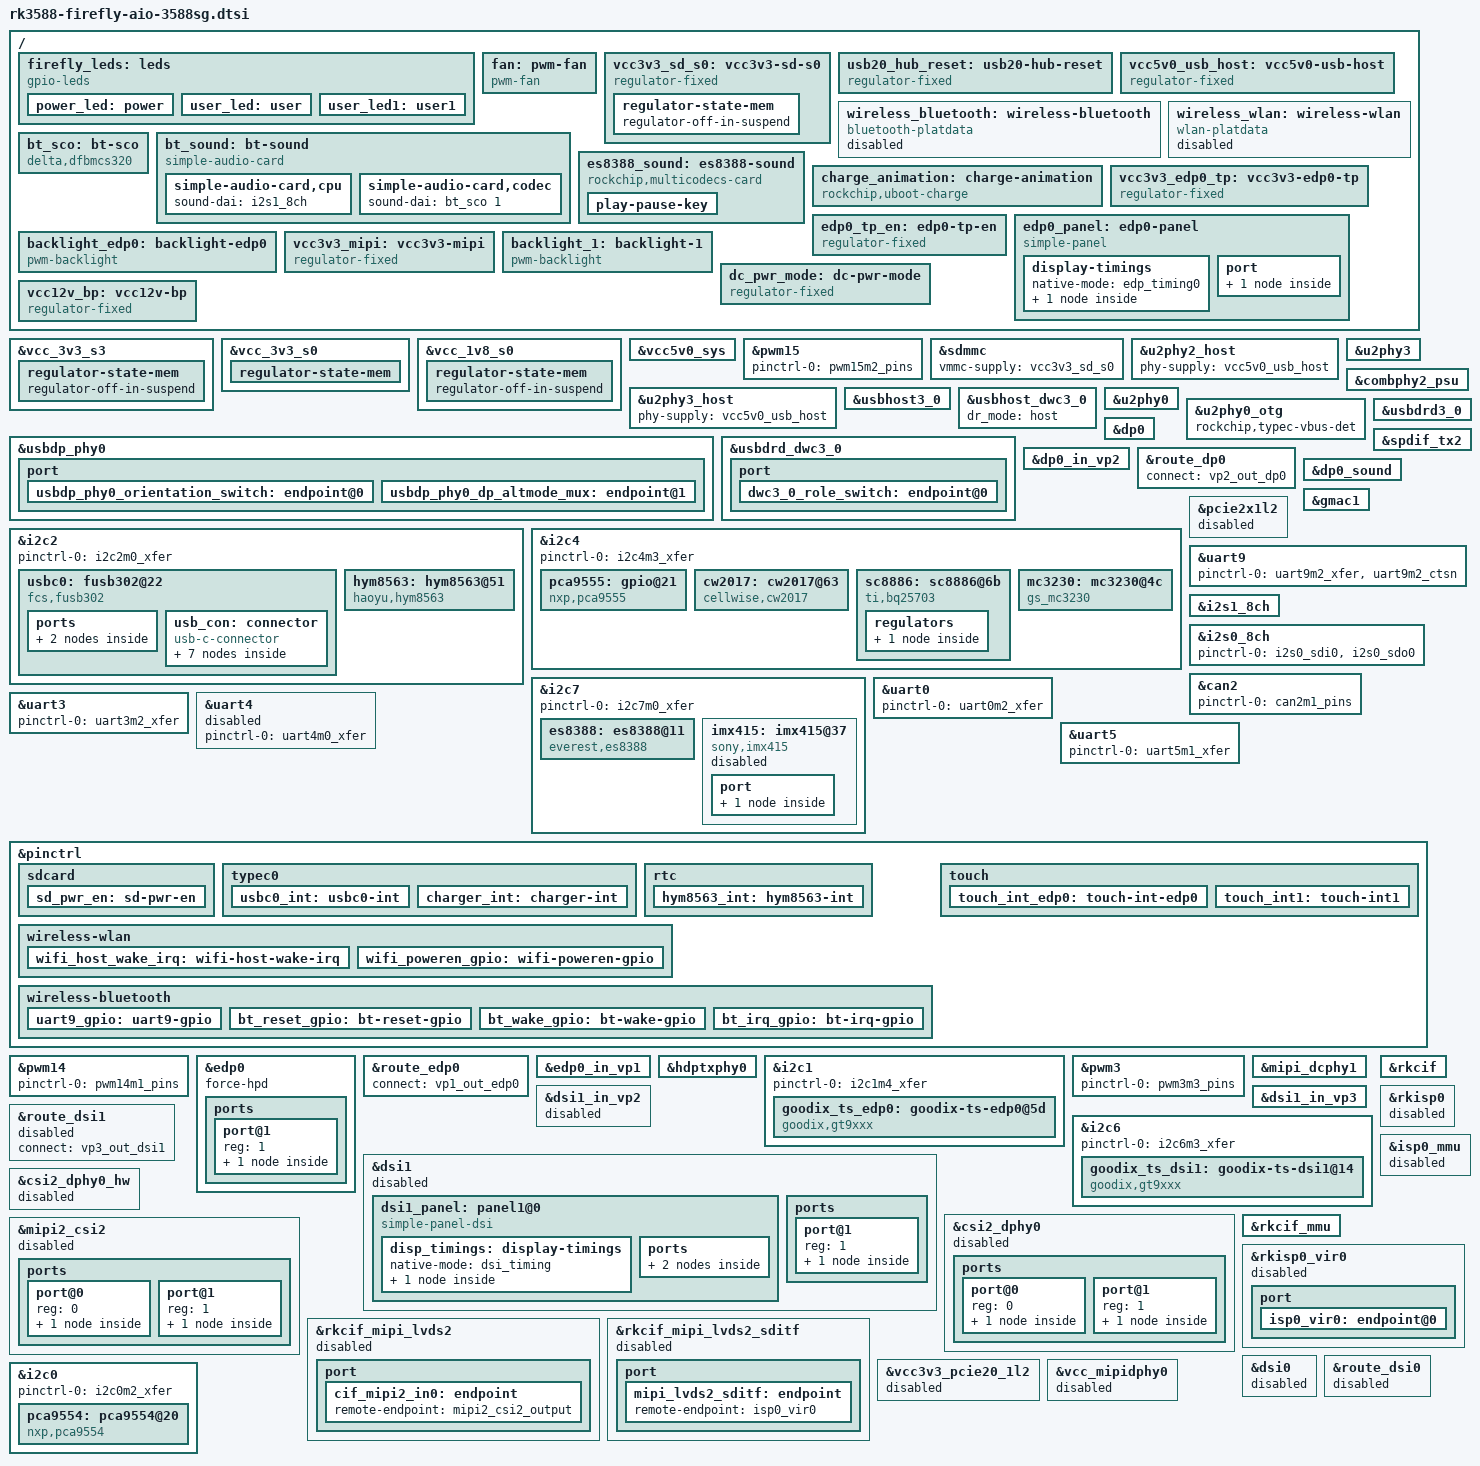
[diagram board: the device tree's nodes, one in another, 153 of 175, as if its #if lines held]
// SPDX-License-Identifier: (GPL-2.0+ OR MIT)
/*
 * Copyright (c) 2023 T-chip Firefly Electronics Co., Ltd.
 *
 */

#include "rk3588-firefly-common.dtsi"

/ {
#ifdef FF_LEDS
	firefly_leds: leds {
		compatible = "gpio-leds";
		status = "okay";

		power_led: power {
			label = ":power";
			linux,default-trigger = "ir-power-click";
			default-state = "on";
			gpios = <&pca9555 PCA_IO1_7 GPIO_ACTIVE_HIGH>;
		};

		user_led: user {
			label = ":user";
			linux,default-trigger = "ir-user-click";
			default-state = "off";
			gpios = <&pca9555 PCA_IO1_6 GPIO_ACTIVE_HIGH>;
		};

		user_led1: user1 {
			label = ":user1";
			linux,default-trigger = "ir-user1-click";
			default-state = "off";
			gpios = <&pca9555 PCA_IO1_5 GPIO_ACTIVE_HIGH>;
		};
	};
#endif

#ifdef FF_FAN
	fan: pwm-fan {
		status = "okay";
		compatible = "pwm-fan";
		#cooling-cells = <2>;
		fan-supply = <&vcc12v_dcin>;
		pwms = <&pwm15 0 50000 0>;
	};
#endif

#ifdef FF_SDCARD
	vcc3v3_sd_s0: vcc3v3-sd-s0 {
		status = "okay";
		compatible = "regulator-fixed";
		regulator-name = "vcc3v3_sd_s0";
		enable-active-high;
		regulator-min-microvolt = <3300000>;
		regulator-max-microvolt = <3300000>;
		gpio = <&gpio3 RK_PC6 GPIO_ACTIVE_HIGH>;
		pinctrl-names = "default";
		pinctrl-0 = <&sd_pwr_en>;
		vin-supply = <&vcc_3v3_s3>;
		regulator-state-mem {
			regulator-off-in-suspend;
		};
	};
#endif

#ifdef FF_USB20_HOST0
	usb20_hub_reset: usb20-hub-reset {
		status = "okay";
		compatible = "regulator-fixed";
		regulator-name = "usb20_hub_reset";
		regulator-boot-on;
		regulator-always-on;
		enable-active-high;
		gpio = <&pca9555 PCA_IO1_4 GPIO_ACTIVE_HIGH>;
	};
#endif

#if defined(FF_USB20_HOST0) || defined(FF_USB30_HOST)
	vcc5v0_usb_host: vcc5v0-usb-host {
		status = "okay";
		compatible = "regulator-fixed";
		regulator-name = "vcc5v0_usb_host";
		enable-active-high;
		regulator-boot-on;
		regulator-always-on;
		regulator-min-microvolt = <5000000>;
		regulator-max-microvolt = <5000000>;
		gpio = <&gpio4 RK_PB5 GPIO_ACTIVE_HIGH>;
		vin-supply = <&vcc5v0_usb>;
	};
#endif

#ifdef FF_WIFIBT
	wireless_bluetooth: wireless-bluetooth {
		compatible = "bluetooth-platdata";
		clocks = <&hym8563>;
		clock-names = "ext_clock";
		uart_rts-gpios = <&gpio3 RK_PD2 GPIO_ACTIVE_LOW>;
		pinctrl-names = "default", "rts_gpio";
		pinctrl-0 = <&uart9m2_rtsn>, <&bt_reset_gpio>, <&bt_wake_gpio>, <&bt_irq_gpio>;
		pinctrl-1 = <&uart9_gpio>;
		BT,reset-gpios      = <&gpio0 RK_PD0 GPIO_ACTIVE_HIGH>;  // BT_REG_ON
		BT,wake-gpios       = <&gpio0 RK_PC6 GPIO_ACTIVE_HIGH>;  // BT_WAKE_APB
		BT,wake_host-gpios  = <&gpio0 RK_PC5 GPIO_ACTIVE_HIGH>;  // BT_HOST_WAKE
		status = "okay";
	};

	wireless_wlan: wireless-wlan {
		compatible = "wlan-platdata";
		wifi_chip_type = "ap6275p";
		pinctrl-names = "default";
		pinctrl-0 = <&wifi_host_wake_irq>, <&wifi_poweren_gpio>;
		WIFI,host_wake-gpios = <&gpio0 RK_PA0 GPIO_ACTIVE_HIGH>;  // WIFI_HOST_WAKE
		WIFI,poweren-gpios   = <&gpio0 RK_PC7 GPIO_ACTIVE_HIGH>;  // WL_REG_ON
		status = "okay";
	};

	bt_sco: bt-sco {
		status = "okay";
		compatible = "delta,dfbmcs320";
		#sound-dai-cells = <1>;
	};

	bt_sound: bt-sound {
		status = "okay";
		compatible = "simple-audio-card";
		simple-audio-card,format = "dsp_a";
		simple-audio-card,bitclock-inversion = <0>;
		simple-audio-card,mclk-fs = <256>;
		simple-audio-card,name = "rockchip,bt";
		simple-audio-card,cpu {
			sound-dai = <&i2s1_8ch>;
		};
		simple-audio-card,codec {
			sound-dai = <&bt_sco 1>;
		};
	};
#endif

#ifdef FF_CODEC_ES8388
	es8388_sound: es8388-sound {
		status = "okay";
		compatible = "rockchip,multicodecs-card";
		rockchip,card-name = "rockchip-es8388";
		//hp-det-gpio = <&gpio3 RK_PC1 GPIO_ACTIVE_LOW>;
		io-channels = <&saradc 4>;
		io-channel-names = "adc-detect";
		keyup-threshold-microvolt = <1800000>;
		poll-interval = <100>;	
		spk-con-gpio = <&gpio1 RK_PC0 GPIO_ACTIVE_HIGH>;
		//hp-con-gpio = <&gpio3 RK_PB2 GPIO_ACTIVE_HIGH>;
		rockchip,format = "i2s";
		rockchip,mclk-fs = <256>;
		rockchip,cpu = <&i2s0_8ch>;
		rockchip,codec = <&es8388>;
		rockchip,audio-routing =
			"Headphone", "LOUT1",
			"Headphone", "ROUT1",
			"Speaker", "LOUT2",
			"Speaker", "ROUT2",
			"Headphone", "Headphone Power",
			"Headphone", "Headphone Power",
			"Speaker", "Speaker Power",
			"Speaker", "Speaker Power",
			"LINPUT1", "Main Mic",
			"LINPUT2", "Main Mic",
			"RINPUT1", "Headset Mic",
			"RINPUT2", "Headset Mic";
		//pinctrl-names = "default";
		//pinctrl-0 = <&hp_det>;
		play-pause-key {
			label = "playpause";
			linux,code = <KEY_PLAYPAUSE>;
			press-threshold-microvolt = <2000>;
		};
	};
#endif

	charge_animation: charge-animation {
		status = "okay";
		compatible = "rockchip,uboot-charge";
		rockchip,uboot-charge-on = <1>;
		rockchip,android-charge-on = <0>;
		rockchip,uboot-exit-charge-level = <2>;
		rockchip,uboot-exit-charge-auto = <1>;
		rockchip,uboot-low-power-voltage = <6144>;
		rockchip,screen-on-voltage = <6144>;
	};
};

&vcc_3v3_s3 {
	regulator-state-mem {
		regulator-off-in-suspend;
	};
};

&vcc_3v3_s0 {
	regulator-state-mem {
		regulator-off-in-suspend;
		regulator-suspend-microvolt = <3300000>;
	};
};

&vcc_1v8_s0 {
	regulator-state-mem {
		regulator-off-in-suspend;
	};

};

&vcc5v0_sys{
	enable-active-high;
	gpio = <&gpio4 RK_PA0 GPIO_ACTIVE_HIGH>;
};

#ifdef FF_FAN
&pwm15 {
	status = "okay";
	pinctrl-0 = <&pwm15m2_pins>;
};
#endif

#ifdef FF_SDCARD
&sdmmc {
	status = "okay";
	vmmc-supply = <&vcc3v3_sd_s0>;
};
#endif

#ifdef FF_USB20_HOST0
&u2phy2_host {
	status = "okay";
	phy-supply = <&vcc5v0_usb_host>;
};
#endif

#ifdef FF_USB30_HOST
&u2phy3 {
	status = "okay";
};

&u2phy3_host {
	status = "okay";
	phy-supply = <&vcc5v0_usb_host>;
};

&combphy2_psu {
	status = "okay";
};

&usbhost3_0 {
	status = "okay";
};

&usbhost_dwc3_0 {
	status = "okay";
	dr_mode = "host";
};
#endif

#ifdef FF_TYPEC0_FULL
&u2phy0 {
	status = "okay";
};

&u2phy0_otg {
	status = "okay";
	rockchip,typec-vbus-det;
};

&usbdp_phy0 {
	status = "okay";
	orientation-switch;
	mode-switch;
	svid = <0xff01>;
	sbu1-dc-gpios = <&gpio1 RK_PB0 GPIO_ACTIVE_HIGH>;
	sbu2-dc-gpios = <&gpio1 RK_PA0 GPIO_ACTIVE_HIGH>;

	port {
		#address-cells = <1>;
		#size-cells = <0>;
		usbdp_phy0_orientation_switch: endpoint@0 {
			reg = <0>;
			remote-endpoint = <&usbc0_orien_sw>;
		};

		usbdp_phy0_dp_altmode_mux: endpoint@1 {
			reg = <1>;
			remote-endpoint = <&dp_altmode_mux>;
		};
	};
};

&usbdrd3_0 {
	status = "okay";
};

&usbdrd_dwc3_0 {
	status = "okay";
	dr_mode = "otg";
	usb-role-switch;
	port {
		#address-cells = <1>;
		#size-cells = <0>;
		dwc3_0_role_switch: endpoint@0 {
			reg = <0>;
			remote-endpoint = <&usbc0_role_sw>;
		};
	};
};

&dp0 {
        status = "okay";
};

&dp0_in_vp2 {
	status = "okay";
};

&spdif_tx2{
        status = "okay";
};

&route_dp0 {
    status = "okay";
    connect = <&vp2_out_dp0>;
};

&dp0_sound{
        status = "okay";
};
#endif

&i2c2 {
	status = "okay";
	pinctrl-names = "default";
	pinctrl-0 = <&i2c2m0_xfer>;

#ifdef FF_TYPEC0_FULL
	usbc0: fusb302@22 {
		compatible = "fcs,fusb302";
		reg = <0x22>;
		interrupt-parent = <&gpio0>;
		interrupts = <RK_PC4 IRQ_TYPE_LEVEL_LOW>;
		int-n-gpios = <&gpio0 RK_PC4 GPIO_ACTIVE_LOW>;
		pinctrl-names = "default";
		pinctrl-0 = <&usbc0_int>;
		vbus-supply = <&vbus5v0_typec_charge>;
		charge-dev = <&sc8886>;
		suspend-disable-irq;
		status = "okay";

		ports {
			#address-cells = <1>;
			#size-cells = <0>;

			port@0 {
				reg = <0>;
				usbc0_role_sw: endpoint@0 {
					remote-endpoint = <&dwc3_0_role_switch>;
				};
			};
		};

		usb_con: connector {
			compatible = "usb-c-connector";
			label = "USB-C";
			data-role = "dual";
			power-role = "dual";
			try-power-role = "sink";
			op-sink-microwatt = <1000000>;
			sink-pdos =
				<PDO_FIXED(5000, 3000, PDO_FIXED_USB_COMM)
				 PDO_FIXED(9000, 3000, PDO_FIXED_USB_COMM)
				 PDO_FIXED(12000, 2000, PDO_FIXED_USB_COMM)>;
			source-pdos = <PDO_FIXED(5000, 3000, PDO_FIXED_USB_COMM)>;
			mode-switch = <&dp0>;

			altmodes {
				#address-cells = <1>;
				#size-cells = <0>;

				altmode@0 {
					reg = <0>;
					svid = /bits/ 16 <0xff01>;
					vdo = <0x00001c46>;
				};
			};

			ports {
				#address-cells = <1>;
				#size-cells = <0>;

				port@0 {
					reg = <0>;
					usbc0_orien_sw: endpoint {
						remote-endpoint = <&usbdp_phy0_orientation_switch>;
					};
				};

				port@1 {
					reg = <1>;
					dp_altmode_mux: endpoint {
						remote-endpoint = <&usbdp_phy0_dp_altmode_mux>;
					};
				};
			};
		};
	};
#endif

#ifdef FF_RTC
	hym8563: hym8563@51 {
		compatible = "haoyu,hym8563";
		reg = <0x51>;
		#clock-cells = <0>;
		clock-frequency = <32768>;
		clock-output-names = "hym8563";
		pinctrl-names = "default";
		pinctrl-0 = <&hym8563_int>;
		interrupt-parent = <&gpio0>;
		interrupts = <RK_PB0 IRQ_TYPE_LEVEL_LOW>;
		wakeup-source;
		status = "okay";
	};
#endif
};

&i2c4 {
	status = "okay";
	pinctrl-names = "default";
	pinctrl-0 = <&i2c4m3_xfer>;
	
#ifdef FF_PCA9555
	pca9555: gpio@21 {
		status = "okay";
		compatible = "nxp,pca9555";
		reg = <0x21>;
		gpio-controller;
		#gpio-cells = <2>;
		gpio-group-num = <200>;
	};
#endif

#ifdef FF_TYPEC0_FULL
	cw2017: cw2017@63 {
		status = "okay";
		compatible = "cellwise,cw2017";
		reg = <0x63>;
		cellwise,battery-profile = /bits/ 8
			<
			0x3C 0x00 0x00 0x00 0x00 0x00 0x00 0x00
			0xB0 0xC4 0xBF 0xB9 0x9B 0x97 0xE0 0xCF
			0xC1 0xCD 0xBB 0x9D 0x88 0x7C 0x65 0x56
			0x52 0x50 0x4E 0x97 0x79 0xD2 0xDE 0xFF
			0xE5 0xB4 0x71 0x7C 0xB0 0xC5 0xAE 0x93
			0x9D 0xB5 0xCF 0xD5 0xC6 0xB0 0x99 0x89
			0x82 0x85 0x91 0xA8 0xC1 0xC9 0xB0 0x43
			0x00 0x00 0x90 0x02 0x00 0x00 0x00 0x00
			0x00 0x00 0x64 0x00 0x00 0x00 0x00 0x00
			0x00 0x00 0x00 0x00 0x00 0x00 0x00 0xA2
			>;
		cellwise,dual-cell;
		cellwise,monitor-interval-ms = <5000>;
		cellwise,alert-level = <10>;
		cellwise,design-capacity-amh = <5000>;
		power-supplies = <&sc8886>;
		firefly,battery-max-voltage = <8400>;
		firefly,battery-min-voltage = <6000>;
		firefly,max-temp = <45>;
		firefly,min-temp = <10>;
	};
		
	sc8886: sc8886@6b {
		status = "okay";
		compatible = "ti,bq25703";
		reg = <0x6b>;
		ti,usb-charger-detection = <&usbc0>;
		ti,charge-current = <2000000>;
		interrupt-parent = <&gpio4>;
		interrupts = <RK_PC1 IRQ_TYPE_LEVEL_LOW>;
		otg-mode-en-gpios = <&gpio4 RK_PC0 GPIO_ACTIVE_HIGH>;
		pinctrl-names = "default";
		pinctrl-0 = <&charger_int>;
		extcon = <&u2phy0>;
		ti,max-input-voltage = <20000000>;
		ti,max-input-current = <6000000>;
		ti,max-charge-voltage = <8400000>;
		ti,input-current = <2500000>;
		ti,input-current-sdp = <2500000>;
		ti,input-current-dcp = <2500000>;
		ti,input-current-cdp = <2500000>;
		ti,minimum-sys-voltage = <6144000>;
		ti,otg-voltage = <5000000>;
		ti,otg-current = <1500000>;
		pd-charge-only = <0>;
		typec0-discharge-gpios = <&gpio1 RK_PA5 GPIO_ACTIVE_HIGH>;
		regulators {
			vbus5v0_typec_charge: vbus5v0-typec-charge {
				regulator-compatible = "otg-vbus";
				regulator-name = "vbus5v0_typec_charge";
			};
		};
	};
#endif

#ifdef FF_GSENSOR
	mc3230: mc3230@4c {
		status = "okay";
		compatible = "gs_mc3230";
		reg = <0x4c>;
		type = <SENSOR_TYPE_ACCEL>;
		irq_enable = <0>;
		poll_delay_ms = <30>;
		layout = <6>;
	};
#endif
};

&i2c7 {
	status = "okay";
	pinctrl-names = "default";
	pinctrl-0 = <&i2c7m0_xfer>;

#ifdef FF_CODEC_ES8388
	es8388: es8388@11 {
		status = "okay";
		#sound-dai-cells = <0>;
		compatible = "everest,es8388", "everest,es8323";
		reg = <0x11>;
		clocks = <&mclkout_i2s0>;
		clock-names = "mclk";
		assigned-clocks = <&mclkout_i2s0>;
		assigned-clock-rates = <12288000>;
		pinctrl-names = "default";
		pinctrl-0 = <&i2s0_mclk>;
	};
#endif
};

#ifdef FF_GMAC1
&gmac1{
 	snps,reset-gpio = <&gpio1 RK_PA1 GPIO_ACTIVE_LOW>;
	tx_delay = <0x37>;
	status = "okay";
};
#endif

#if defined(FF_PCIE2_1L2) && !defined(FF_SATA0)
&pcie2x1l2 {
	reset-gpios = <&gpio3 RK_PD1 GPIO_ACTIVE_HIGH>;
	rockchip,skip-scan-in-resume;
	status = "okay";
};
#endif


#ifdef FF_WIFIBT
&uart9 {
	status = "okay";
	pinctrl-names = "default";
	pinctrl-0 = <&uart9m2_xfer &uart9m2_ctsn>;
};

&i2s1_8ch {
	status = "okay";
	pinctrl-0 = <&i2s1m0_lrck
		     &i2s1m0_sclk
		     &i2s1m0_sdi2
		     &i2s1m0_sdo3>;
	rockchip,bclk-fs = <32>;
};
#endif

#ifdef FF_CODEC_ES8388
&i2s0_8ch {
	status = "okay";
	pinctrl-0 = <&i2s0_sdi0 &i2s0_sdo0>;
};
#endif

#ifdef FF_CAN2
&can2 {
	status = "okay";
	pinctrl-names = "default";
	pinctrl-0 = <&can2m1_pins>;
};
#endif

#ifdef FF_UART
&uart0 {
	status = "okay";
	pinctrl-names = "default";
	pinctrl-0 = <&uart0m2_xfer>;
};

&uart3 {
	status = "okay";
	pinctrl-names = "default";
	pinctrl-0 = <&uart3m2_xfer>;
};

&uart4 {
	status = "okay";
	pinctrl-names = "default";
	pinctrl-0 = <&uart4m0_xfer>;
};

&uart5 {
	status = "okay";
	pinctrl-names = "default";
	pinctrl-0 = <&uart5m1_xfer>;
};
#endif

&pinctrl {
#ifdef FF_SDCARD
	sdcard {
		sd_pwr_en: sd-pwr-en {
			rockchip,pins = <3 RK_PC6 RK_FUNC_GPIO &pcfg_pull_none>;
		};
	};
#endif

#ifdef FF_TYPEC0_FULL
	typec0 {
		usbc0_int: usbc0-int {
			rockchip,pins = <0 RK_PC4 RK_FUNC_GPIO &pcfg_pull_up>;
		};

		charger_int: charger-int {
			rockchip,pins = <4 RK_PC1 RK_FUNC_GPIO &pcfg_pull_up>;
		};
	};
#endif

#ifdef FF_RTC
	rtc {
		hym8563_int: hym8563-int {
			rockchip,pins = <0 RK_PB0 RK_FUNC_GPIO &pcfg_pull_up>;
		};
	};
#endif

#ifdef FF_WIFIBT
	wireless-wlan {
		wifi_host_wake_irq: wifi-host-wake-irq {
			rockchip,pins = <0 RK_PA0 RK_FUNC_GPIO &pcfg_pull_down>;
		};

		wifi_poweren_gpio: wifi-poweren-gpio {
			rockchip,pins = <0 RK_PC7 RK_FUNC_GPIO &pcfg_pull_up>;
		};
	};

	wireless-bluetooth {
		uart9_gpio: uart9-gpio {
			rockchip,pins = <3 RK_PD2 RK_FUNC_GPIO &pcfg_pull_none>;
		};
		bt_reset_gpio: bt-reset-gpio {
			rockchip,pins = <0 RK_PD0 RK_FUNC_GPIO &pcfg_pull_none>;
		};

		bt_wake_gpio: bt-wake-gpio {
			rockchip,pins = <0 RK_PC6 RK_FUNC_GPIO &pcfg_pull_none>;
		};

		bt_irq_gpio: bt-irq-gpio {
			rockchip,pins = <0 RK_PC5 RK_FUNC_GPIO &pcfg_pull_down>;
		};
	};
#endif
};

#ifdef FF_EDP0_VP1
/* ===== inlined from top-level dts: #include "rk3588-firefly-aio-3588sg-edp0.dtsi" ===== */
// SPDX-License-Identifier: (GPL-2.0+ OR MIT)
/*
 * Copyright (c) 2023 Rockchip Electronics Co., Ltd.
 *
 */

/ {
	vcc3v3_edp0_tp: vcc3v3-edp0-tp {
		status = "okay";
		compatible = "regulator-fixed";
		regulator-name = "vcc3v3_edp0_tp";
		regulator-boot-on;
		regulator-always-on;
		enable-active-high;
		gpio = <&pca9554 PCA_IO0_1 GPIO_ACTIVE_HIGH>;
	};

	edp0_tp_en: edp0-tp-en {
		status = "okay";
		compatible = "regulator-fixed";
		regulator-name = "edp0_tp_en";
		regulator-boot-on;
		regulator-always-on;
		enable-active-high;
		gpio = <&pca9554 PCA_IO0_2 GPIO_ACTIVE_HIGH>;
	};

	edp0_panel: edp0-panel {
		status = "okay";
		compatible = "simple-panel";
		backlight = <&backlight_edp0>;
		enable-gpios = <&pca9555 PCA_IO0_3 GPIO_ACTIVE_HIGH>;
		prepare-delay-ms = <200>;

		display-timings {
			native-mode = <&edp_timing0>;
			edp_timing0: timing0 {
				clock-frequency = <533250000>;  // Min 355.52 / Typ 533.25 / Max 586.6  (MHz)
				hactive = <3840>;
				vactive = <2160>;
				hfront-porch = <48>;
				hsync-len = <32>;
				hback-porch = <100>;
				vfront-porch = <3>;
				vsync-len = <5>;
				vback-porch = <30>;
				hsync-active = <0>;
				vsync-active = <0>;
				de-active = <0>;
				pixelclk-active = <0>;
			};
		};

		port {
			panel_in_edp0: endpoint {
				remote-endpoint = <&edp0_out_panel>;
			};
		};
	};

	backlight_edp0: backlight-edp0 {
		status = "okay";
		compatible = "pwm-backlight";
		enable-gpios = <&pca9555 PCA_IO0_2 GPIO_ACTIVE_HIGH>; // EDP_BL_EN
		pwms = <&pwm14 0 50000 0>;
		brightness-levels = <
			  0   1   2   3   4   5   6   7
			  8   9  10  11  12  13  14  15
			 16  17  18  19  20  21  22  23
			 24  25  26  27  28  29  30  31
			 32  33  34  35  36  37  38  39
			 40  41  42  43  44  45  46  47
			 48  49  50  51  52  53  54  55
			 56  57  58  59  60  61  62  63
			 64  65  66  67  68  69  70  71
			 72  73  74  75  76  77  78  79
			 80  81  82  83  84  85  86  87
			 88  89  90  91  92  93  94  95
			 96  97  98  99 100 101 102 103
			104 105 106 107 108 109 110 111
			112 113 114 115 116 117 118 119
			120 121 122 123 124 125 126 127
			128 129 130 131 132 133 134 135
			136 137 138 139 140 141 142 143
			144 145 146 147 148 149 150 151
			152 153 154 155 156 157 158 159
			160 161 162 163 164 165 166 167
			168 169 170 171 172 173 174 175
			176 177 178 179 180 181 182 183
			184 185 186 187 188 189 190 191
			192 193 194 195 196 197 198 199
			200 201 202 203 204 205 206 207
			208 209 210 211 212 213 214 215
			216 217 218 219 220 221 222 223
			224 225 226 227 228 229 230 231
			232 233 234 235 236 237 238 239
			240 241 242 243 244 245 246 247
			248 249 250 251 252 253 254 255 >;
		default-brightness-level = <200>;
	};
};

&pwm14 {
	status = "okay";
	pinctrl-0 = <&pwm14m1_pins>;
};

&edp0 {
	status = "okay";
	force-hpd;
	//hpd-gpios = <&gpio1 RK_PA6 GPIO_ACTIVE_HIGH>;

	ports {
		port@1 {
			reg = <1>;
			edp0_out_panel: endpoint {
				remote-endpoint = <&panel_in_edp0>;
			};
		};
	};
};

&route_edp0 {
	status = "okay";
	connect = <&vp1_out_edp0>;
};

&edp0_in_vp1 {
	status = "okay";
};

&hdptxphy0 {
	status = "okay";
};

&i2c1 {
	status = "okay";
	pinctrl-names = "default";
	pinctrl-0 = <&i2c1m4_xfer>;

	goodix_ts_edp0: goodix-ts-edp0@5d {
		status = "okay";
		compatible = "goodix,gt9xxx";
		reg = <0x5d>;
		interrupt-parent = <&gpio1>;
		interrupts = <RK_PB2 IRQ_TYPE_LEVEL_LOW>;
		reset-gpios = <&pca9554 PCA_IO0_3 GPIO_ACTIVE_LOW>;
		irq-gpios = <&gpio1 RK_PB2 IRQ_TYPE_EDGE_FALLING>;
		irq-flags = <2>; /* 1 rising, 2 falling */
		pinctrl-names = "default";
		pinctrl-0 = <&touch_int_edp0>;
		touchscreen-size-x = <3840>;
		touchscreen-size-y = <2160>;
		goodix,slide-wakeup = <0>;
		goodix,type-a-report = <1>;
		goodix,driver-send-cfg = <1>;
		goodix,resume-in-workqueue = <0>;
		goodix,int-sync = <0>;
		goodix,esd-protect = <0>;
		goodix,auto-update-cfg = <1>;
		goodix,auto-update = <0>;
		goodix,power-off-sleep = <0>;
		goodix,pen-suppress-finger = <0>;
		goodix,has-pen = <0>;

		goodix,cfg-group2 = [
			5a 00 40 80 25 0a 7d 00 01 08
			28 05 5f 32 03 05 00 00 00 00
			00 00 00 1a 1c 1e 14 95 35 ff
			2a 2c b5 06 00 00 02 b9 03 1d
			1a 1c 1e 90 00 00 00 00 00 00
			00 1e 42 94 c5 02 07 00 00 04
			f5 20 00 c7 26 00 a6 2c 00 8a
			34 00 73 3d 00 73 00 00 00 00
			00 00 00 00 00 00 00 00 00 00
			00 00 00 00 00 00 00 00 00 00
			00 00 00 00 03 00 00 00 00 00
			00 00 00 01 02 03 04 05 06 07
			08 09 0a 0b 0c 0d 0e 0f 10 11
			12 13 14 15 16 17 18 19 1a 1b
			1c 1d 2a 29 28 27 26 25 24 23
			22 21 20 1f 1e 1d 1c 1b 19 18
			17 16 15 14 13 12 11 10 0f 0e
			0d 0c 0b 0a 09 08 07 06 05 04
			03 02 01 00 cc 01];
	};
};

&pinctrl {
	touch {
		touch_int_edp0: touch-int-edp0 {
			rockchip,pins = <1 RK_PB2 RK_FUNC_GPIO &pcfg_pull_up>;
		};
	};
};
#endif

#if defined(FF_DSI1_VP3) && !defined(FF_DSI0_LVDS101_VP3) && !defined(FF_DSI0_LVDS215_VP3)
/* ===== inlined from top-level dts: #include "rk3588-firefly-aio-3588sg-mipi-dsi1.dtsi" ===== */
// SPDX-License-Identifier: (GPL-2.0+ OR MIT)
/*
 * Copyright (c) 2023 Rockchip Electronics Co., Ltd.
 *
 */

#include <dt-bindings/display/drm_mipi_dsi.h>

/ {
	vcc3v3_mipi: vcc3v3-mipi {
		status = "okay";
		compatible = "regulator-fixed";
		regulator-name = "vcc3v3_mipi";
		regulator-boot-on;
		regulator-always-on;
		enable-active-high;
		gpio = <&pca9555 PCA_IO0_6 GPIO_ACTIVE_HIGH>;
	};

	backlight_1: backlight-1 {
		status = "okay";
		compatible = "pwm-backlight";
		enable-gpios = <&gpio4 RK_PB7 GPIO_ACTIVE_HIGH>;
		pwms = <&pwm3 0 50000 1>;
		brightness-levels = <
			 60  60  60  61  61  61  62  62
			 62  63  63  63  64  64  64  65
			 65  65  66  66  66  67  67  67
			 68  68  68  69  69  69  70  70
			 70  71  71  71  72  72  72  73
			 73  73  74  74  74  75  75  75
			 76  76  76  77  77  77  78  78
			 78  79  79  79  80  80  80  81
			 81  81  82  82  82  83  83  83
			 84  84  84  85  85  85  86  86
			 86  87  87  87  88  88  88  89
			 89  89  90  91  92  93  94  95
			 96  97  98  99 100 101 102 103
			104 105 106 107 108 109 110 111
			112 113 114 115 116 117 118 119
			120 121 122 123 124 125 126 127
			128 129 130 131 132 133 134 135
			136 137 138 139 140 141 142 143
			144 145 146 147 148 149 150 151
			152 153 154 155 156 157 158 159
			160 161 162 163 164 165 166 167
			168 169 170 171 172 173 174 175
			176 177 178 179 180 181 182 183
			184 185 186 187 188 189 190 191
			192 193 194 195 196 197 198 199
			200 201 202 203 204 205 206 207
			208 209 210 211 212 213 214 215
			216 217 218 219 220 221 222 223
			224 225 226 227 228 229 230 231
			232 233 234 235 236 237 238 239
			240 241 242 243 244 245 246 247
			248 249 250 251 252 253 254 255 >;
		default-brightness-level = <200>;
	};
};

&pwm3 {
	pinctrl-0 = <&pwm3m3_pins>;
	status = "okay";
};

/*
 * mipi_dcphy1 needs to be enabled
 * when dsi1 is enabled
 */
&mipi_dcphy1 {
	status = "okay";
};

&dsi1_in_vp2 {
	status = "disabled";
};

&dsi1_in_vp3 {
	status = "okay";
};

&route_dsi1 {
	status = "okay";
	connect = <&vp3_out_dsi1>;
};

&dsi1 {
	status = "okay";
	/*
	 * firefly-check / 0x99 ID-check cmd are Firefly private features
	 * of the 6.1 BSP driver (panel-simple.c + dw-mipi-dsi2-rockchip.c);
	 * they are not ported to 6.12, keep them off here.
	 */
	//firefly-check;

	dsi1_panel: panel1@0 {
		status = "okay";
		compatible = "simple-panel-dsi";
		reg = <0>;
		backlight = <&backlight_1>;

		enable-gpios = <&pca9555 PCA_IO0_5 GPIO_ACTIVE_HIGH>;
		reset-gpios = <&pca9555 PCA_IO0_4 GPIO_ACTIVE_LOW>;

		enable-delay-ms = <50>;
		prepare-delay-ms = <200>;
		reset-delay-ms = <50>;
		init-delay-ms = <55>;
		unprepare-delay-ms = <50>;
		disable-delay-ms = <20>;
		mipi-data-delay-ms = <200>;
		size,width = <120>;
		size,height = <170>;
		dsi,flags = <(MIPI_DSI_MODE_VIDEO | MIPI_DSI_MODE_VIDEO_BURST | MIPI_DSI_MODE_LPM | MIPI_DSI_MODE_NO_EOT_PACKET)>;
		dsi,format = <MIPI_DSI_FMT_RGB888>;
		dsi,lanes = <4>;

		/*
		 * Panel presence check done by U-Boot: select page 1, then read
		 * register 0x00 and expect 0x98. When no MIPI panel is attached
		 * U-Boot disables this panel, its touch device, the dsi1
		 * controller and its route in the FDT passed to the kernel, so
		 * the kernel does not create a dead DSI connector that keeps
		 * the DRM component master deferred and blocks HDMI output.
		 * Same fix as ITX-3588J (commit 3270494f67d6).
		 */
		panel-read-id-sequence = [
			39 00 04 FF 98 81 01
		];
		id-reg = <0x00>;
		id = [98];

		/* touch device bound to this panel, disabled together */
		rockchip,touch-nodes = <&goodix_ts_dsi1>;

		panel-init-sequence = [
			39 00 04 FF 98 81 01
			39 00 04 FF 98 81 03
			15 00 02 01 00
			15 00 02 02 00
			15 00 02 03 55
			15 00 02 04 55
			15 00 02 05 03
			15 00 02 06 06
			15 00 02 07 00
			15 00 02 08 07
			15 00 02 09 00
			15 00 02 0a 00
			15 00 02 0b 00
			15 00 02 0c 00
			15 00 02 0d 00
			15 00 02 0e 00
			15 00 02 0f 00

			15 00 02 10 00
			15 00 02 11 00
			15 00 02 12 00
			15 00 02 13 00
			15 00 02 14 00
			15 00 02 15 00
			15 00 02 16 00
			15 00 02 17 00
			15 00 02 18 00
			15 00 02 19 00
			15 00 02 1a 00
			15 00 02 1b 00
			15 00 02 1c 00
			15 00 02 1d 00
			15 00 02 1e C0
			15 00 02 1f 80

			15 00 02 20 04
			15 00 02 21 03
			15 00 02 22 00
			15 00 02 23 00
			15 00 02 24 00
			15 00 02 25 00
			15 00 02 26 00
			15 00 02 27 00
			15 00 02 28 33
			15 00 02 29 33
			15 00 02 2a 00
			15 00 02 2b 00
			15 00 02 2c 00
			15 00 02 2d 00
			15 00 02 2e 00
			15 00 02 2f 00

			15 00 02 30 00
			15 00 02 31 00
			15 00 02 32 00
			15 00 02 33 00
			15 00 02 34 04
			15 00 02 35 00
			15 00 02 36 00
			15 00 02 37 00
			15 00 02 38 3C
			15 00 02 39 00
			15 00 02 3a 00
			15 00 02 3b 00
			15 00 02 3c 00
			15 00 02 3d 00
			15 00 02 3e 00
			15 00 02 3f 00

			15 00 02 40 00
			15 00 02 41 00
			15 00 02 42 00
			15 00 02 43 00
			15 00 02 44 00

			15 00 02 50 00
			15 00 02 51 11
			15 00 02 52 44
			15 00 02 53 55
			15 00 02 54 88
			15 00 02 55 AB
			15 00 02 56 00
			15 00 02 57 11
			15 00 02 58 22
			15 00 02 59 33
			15 00 02 5a 44
			15 00 02 5b 55
			15 00 02 5c 66
			15 00 02 5d 77
			15 00 02 5e 00
			15 00 02 5f 02

			15 00 02 60 02
			15 00 02 61 0A
			15 00 02 62 09
			15 00 02 63 08
			15 00 02 64 13
			15 00 02 65 12
			15 00 02 66 11
			15 00 02 67 10
			15 00 02 68 0F
			15 00 02 69 0E
			15 00 02 6a 0D
			15 00 02 6b 0C
			15 00 02 6c 06
			15 00 02 6d 07
			15 00 02 6e 02
			15 00 02 6f 02

			15 00 02 70 02
			15 00 02 71 02
			15 00 02 72 02
			15 00 02 73 02
			15 00 02 74 02
			15 00 02 75 02
			15 00 02 76 02
			15 00 02 77 0A
			15 00 02 78 06
			15 00 02 79 07
			15 00 02 7a 10
			15 00 02 7b 11
			15 00 02 7c 12
			15 00 02 7d 13
			15 00 02 7e 0C
			15 00 02 7f 0D

			15 00 02 80 0E
			15 00 02 81 0F
			15 00 02 82 09
			15 00 02 83 08
			15 00 02 84 02
			15 00 02 85 02
			15 00 02 86 02
			15 00 02 87 02
			15 00 02 88 02
			15 00 02 89 02
			15 00 02 8A 02

			39 00 04 FF 98 81 04
			15 00 02 6E 2A
			15 00 02 6F 37
			15 00 02 3A 24
			15 00 02 8D 19
			15 00 02 87 BA
			15 00 02 B2 D1
			15 00 02 88 0B
			15 00 02 38 01
			15 00 02 39 00
			15 00 02 B5 02
			15 00 02 31 25
			15 00 02 3B 98
			39 00 04 FF 98 81 01

			15 00 02 22 0A
			15 00 02 31 0C
			15 00 02 53 40
			15 00 02 55 45
			15 00 02 50 B7
			15 00 02 51 B2
			15 00 02 60 07

			15 00 02 A0 22
			15 00 02 A1 3F
			15 00 02 A2 4E
			15 00 02 A3 17
			15 00 02 A4 1A
			15 00 02 A5 2D
			15 00 02 A6 21
			15 00 02 A7 22
			15 00 02 A8 C4
			15 00 02 A9 1B
			15 00 02 AA 25
			15 00 02 AB A7
			15 00 02 AC 1A
			15 00 02 AD 19
			15 00 02 AE 4B
			15 00 02 AF 1F

			15 00 02 B0 2A
			15 00 02 B1 59
			15 00 02 B2 64
			15 00 02 B3 3F

			15 00 02 C0 22
			15 00 02 C1 48
			15 00 02 C2 59
			15 00 02 C3 15
			15 00 02 C4 15
			15 00 02 C5 28
			15 00 02 C6 1C
			15 00 02 C7 1E
			15 00 02 C8 C4
			15 00 02 C9 1C
			15 00 02 CA 2B
			15 00 02 CB A3
			15 00 02 CC 1F
			15 00 02 CD 1E
			15 00 02 CE 52
			15 00 02 CF 24

			15 00 02 D0 2A
			15 00 02 D1 58
			15 00 02 D2 68
			15 00 02 D3 3F
			39 00 04 FF 98 81 00
			05 78 01 11			 //Delay 120ms
			05 14 01 29			 //Delay 20ms
		];

		panel-exit-sequence = [
			39 00 04 FF 98 81 00		//page0
			05 14 01 28				//Delay 20ms
			05 78 01 10				//Delay 120ms
		];

		disp_timings: display-timings {
			native-mode = <&dsi_timing>;
			dsi_timing: timing {
				clock-frequency = <70000000>;//<80000000>;
				hactive = <800>;//<768>;
				vactive = <1280>;
				hsync-len = <20>;   //20, 50,10
				hback-porch = <20>; //50, 56,10
				hfront-porch = <40>;//50, 30,180
				vsync-len = <4>;//4
				vback-porch = <20>;//4
				vfront-porch = <20>;//8
				hsync-active = <0>;
				vsync-active = <0>;
				de-active = <0>;
				pixelclk-active = <0>;
			};
		};

		ports {
			#address-cells = <1>;
			#size-cells = <0>;

			port@0 {
				reg = <0>;
				panel_in_dsi1: endpoint {
					remote-endpoint = <&dsi1_out_panel>;
				};
			};
		};
	};

	ports {
		#address-cells = <1>;
		#size-cells = <0>;

		port@1 {
			reg = <1>;
			dsi1_out_panel: endpoint {
			remote-endpoint = <&panel_in_dsi1>;
			};
		};
	};
};

&i2c6 {
	status = "okay";
	pinctrl-names = "default";
	pinctrl-0 = <&i2c6m3_xfer>;

	goodix_ts_dsi1: goodix-ts-dsi1@14 {
		status = "okay";
		compatible = "goodix,gt9xxx";
		reg = <0x14>;
		interrupt-parent = <&gpio1>;
		interrupts = <RK_PB5 IRQ_TYPE_LEVEL_LOW>;
		reset-gpios = <&pca9555 PCA_IO0_7 GPIO_ACTIVE_HIGH>;
		irq-gpios = <&gpio1 RK_PB5 IRQ_TYPE_LEVEL_LOW>;
		irq-flags = <2>; /* 1 rising, 2 falling */
		pinctrl-names = "default";
		pinctrl-0 = <&touch_int1>;
		touchscreen-size-x = <800>;
		touchscreen-size-y = <1280>;
		goodix,slide-wakeup = <0>;
		goodix,type-a-report = <1>;
		goodix,driver-send-cfg = <1>;
		goodix,resume-in-workqueue = <0>;
		goodix,int-sync = <1>;
		goodix,esd-protect = <1>;
		goodix,auto-update-cfg = <1>;
		goodix,auto-update = <0>;
		goodix,power-off-sleep = <0>;
		goodix,pen-suppress-finger = <0>;
		goodix,has-pen = <0>;

		goodix,cfg-group2 = [
			62 20 03 00 05 0A 35 00 01
			0A 28 0F 50 3C 03 05 00 00
			00 00 00 00 06 18 1A 1E 14
			90 30 AA 37 39 12 0C 00 00
			00 1A 02 2D 00 00 00 00 00
			00 00 00 07 00 00 28 4B 94
			D5 02 07 00 00 04 9A 2A 00
			8C 30 00 81 36 00 76 3E 00
			6E 46 00 6E 00 00 00 00 00
			00 00 00 00 00 00 00 00 00
			00 00 00 00 00 00 00 00 00
			00 00 00 00 00 02 00 00 00
			00 00 00 00 19 18 17 16 15
			14 11 10 0F 0E 0D 0C 09 08
			07 06 05 04 01 00 00 00 00
			00 00 00 00 00 00 00 14 13
			12 11 10 0F 0E 0D 0C 0A 08
			07 06 04 02 00 19 1B 1C 1E
			1F 20 21 22 23 24 25 26 27
			28 29 2A 00 00 00 00 00 00
			00 00 00 00 D8 01];
	};
};

&pinctrl {
	touch {
		touch_int1: touch-int1 {
			rockchip,pins = <1 RK_PB5 RK_FUNC_GPIO &pcfg_pull_up>;
		};
	};
};
#endif

#ifdef FF_MIPI_CSI2_IMX415
/* ===== inlined from top-level dts: #include "rk3588-firefly-aio-3588sg-mipi-csi2-imx415.dtsi" ===== */
// SPDX-License-Identifier: (GPL-2.0+ OR MIT)
/*
 * Copyright (c) 2021 Rockchip Electronics Co., Ltd.
 *
 */

&i2c7 {
	status = "okay";
	pinctrl-names = "default";
	pinctrl-0 = <&i2c7m0_xfer>;

	imx415: imx415@37 {
		compatible = "sony,imx415";
		reg = <0x37>;
		clocks = <&cru CLK_MIPI_CAMARAOUT_M1>;
		clock-names = "xvclk";
		pinctrl-names = "default";
		pinctrl-0 = <&mipim1_camera1_clk>;
		power-domains = <&power RK3588_PD_VI>;

                reset-gpios = <&gpio1 RK_PD5 GPIO_ACTIVE_LOW>;

		rockchip,camera-module-index = <0>;
		rockchip,camera-module-facing = "back";
		rockchip,camera-module-name = "CMK-OT2022-PX1";
		rockchip,camera-module-lens-name = "IR0147-50IRC-8M-F20";
		//lens-focus = <&cam_ircut0>;
		port {
			imx415_out: endpoint {
				remote-endpoint = <&mipidphy0_in_ucam1>;
				data-lanes = <1 2 3 4>;
			};
		};
	};

};

&csi2_dphy0_hw {
	status = "okay";
};

&csi2_dphy0 {
	status = "okay";

	ports {
		#address-cells = <1>;
		#size-cells = <0>;
		port@0 {
			reg = <0>;
			#address-cells = <1>;
			#size-cells = <0>;

			mipidphy0_in_ucam1: endpoint@1 {
				reg = <1>;
				remote-endpoint = <&imx415_out>;
				data-lanes = <1 2 3 4>;
			};
		};
		port@1 {
			reg = <1>;
			#address-cells = <1>;
			#size-cells = <0>;

			csidphy0_out: endpoint@0 {
				reg = <0>;
				remote-endpoint = <&mipi2_csi2_input>;
			};
		};
	};
};

&mipi2_csi2 {
	status = "okay";

	ports {
		#address-cells = <1>;
		#size-cells = <0>;

		port@0 {
			reg = <0>;
			#address-cells = <1>;
			#size-cells = <0>;

			mipi2_csi2_input: endpoint@0 {
				reg = <0>;
				remote-endpoint = <&csidphy0_out>;
			};
		};

		port@1 {
			reg = <1>;
			#address-cells = <1>;
			#size-cells = <0>;

			mipi2_csi2_output: endpoint@0 {
				reg = <0>;
				remote-endpoint = <&cif_mipi2_in0>;
			};
		};
	};
};

&rkcif {
	status = "okay";
};

&rkcif_mmu {
	status = "okay";
};

&rkcif_mipi_lvds2 {
	status = "okay";

	port {
		cif_mipi2_in0: endpoint {
			remote-endpoint = <&mipi2_csi2_output>;
		};
	};
};

&rkcif_mipi_lvds2_sditf {
	status = "okay";

	port {
		mipi_lvds2_sditf: endpoint {
			remote-endpoint = <&isp0_vir0>;
		};
	};
};

&rkisp0 {
	status = "okay";
};

&isp0_mmu {
	status = "okay";
};

&rkisp0_vir0 {
	status = "okay";

	port {
		#address-cells = <1>;
		#size-cells = <0>;

		isp0_vir0: endpoint@0 {
			reg = <0>;
			remote-endpoint = <&mipi_lvds2_sditf>;
		};
	};
};
#endif

#ifdef FF_BP
/* ===== inlined from top-level dts: #include "rk3588-firefly-aio-3588sg-bp.dtsi" ===== */
// SPDX-License-Identifier: (GPL-2.0+ OR MIT)
/*
 * Copyright (c) 2023 Rockchip Electronics Co., Ltd.
 *
 */

#if defined(FF_DSI0_LVDS101_VP3) && !defined(FF_DSI0_LVDS215_VP3) && !defined(FF_DSI1_VP3)
#include "rk3588-firefly-aio-3588sg-mipi-dsi0-lvds101.dtsi"
#endif

#if defined(FF_DSI0_LVDS215_VP3) && !defined(FF_DSI0_LVDS101_VP3) && !defined(FF_DSI1_VP3)
#include "rk3588-firefly-aio-3588sg-mipi-dsi0-lvds215.dtsi"
#endif

#if defined(FF_MIPI_CSI2_CAMERA1_XC7160) && \
   !defined(FF_MIPI_CSI2_CAMERA2_XC7160)
#include "rk3588-firefly-aio-3588sg-mipi-csi2-camera1-xc7160.dtsi"
#endif

#if defined(FF_MIPI_CSI2_CAMERA2_XC7160) && \
   !defined(FF_MIPI_CSI2_CAMERA1_XC7160)
#include "rk3588-firefly-aio-3588sg-mipi-csi2-camera2-xc7160.dtsi"
#endif

#if defined(FF_MIPI_CSI2_CAMERA1_XC7160) && \
    defined(FF_MIPI_CSI2_CAMERA2_XC7160)
#include "rk3588-firefly-aio-3588sg-mipi-csi2-camera-xc7160x2.dtsi"
#endif

#if defined(FF_MIPI_CSI2_CAMERA1_XC7160)
&dsi0 {
	status = "disabled";
};

&route_dsi0 {
	status = "disabled";
};

&uart4 {
	status = "disabled";
};

#ifdef FF_PCIE2_1L2
&pcie2x1l2 {
	status = "disabled";
};

&vcc3v3_pcie20_1l2 {
	status = "disabled";
};
#endif

#ifdef FF_WIFIBT
&wireless_wlan {
	status = "disabled";
};

&wireless_bluetooth {
	status = "disabled";
};
#endif
#endif

#if (defined(FF_MIPI_CSI2_CAMERA1_XC7160) || \
     defined(FF_MIPI_CSI2_CAMERA2_XC7160)) && \
    defined(FF_MIPI_CSI2_IMX415)
/* XC7160 is selected; disable the alternative IMX415 CSI/ISP pipeline. */
&imx415 {
	status = "disabled";
};

&csi2_dphy0 {
	status = "disabled";
};

&csi2_dphy0_hw {
	status = "disabled";
};

&mipi2_csi2 {
	status = "disabled";
};

&rkcif_mipi_lvds2 {
	status = "disabled";
};

&rkcif_mipi_lvds2_sditf {
	status = "disabled";
};

&rkisp0 {
	status = "disabled";
};

&isp0_mmu {
	status = "disabled";
};

&rkisp0_vir0 {
	status = "disabled";
};

&vcc_mipidphy0 {
	status = "disabled";
};
#endif

#if defined(FF_MIPI_CSI2_CAMERA2_XC7160) && !defined(FF_MIPI_CSI2_CAMERA1_XC7160)
&dsi1 {
	status = "disabled";
};

&route_dsi1 {
	status = "disabled";
};
#endif

#if defined(FF_MIPI_CSI2_CAMERA1_XC7160) && defined(FF_MIPI_CSI2_CAMERA2_XC7160)
&dsi0 {
	status = "disabled";
};

&route_dsi0 {
	status = "disabled";
};

&dsi1 {
	status = "disabled";
};

&route_dsi1 {
	status = "disabled";
};
#endif

/ {
	dc_pwr_mode: dc-pwr-mode {
		status = "okay";
		compatible = "regulator-fixed";
		regulator-name = "dc_pwr_mode";
		regulator-boot-on;
		regulator-always-on;
		enable-active-high;
		gpio = <&pca9554 PCA_IO0_7 GPIO_ACTIVE_HIGH>;
	};

	vcc12v_bp: vcc12v-bp {
		status = "okay";
		compatible = "regulator-fixed";
		regulator-name = "vcc12v_bp";
		regulator-boot-on;
		regulator-always-on;
		enable-active-high;
		gpio = <&gpio1 RK_PB3 GPIO_ACTIVE_HIGH>;
	};
};

&i2c0 {
	status = "okay";
	pinctrl-0 = <&i2c0m2_xfer>;

	pca9554: pca9554@20 {
		status = "okay";
		compatible = "nxp,pca9554";
		reg = <0x20>;
		gpio-controller;
		#gpio-cells = <2>;
		gpio-group-num = <180>;
	};
};
#endif
